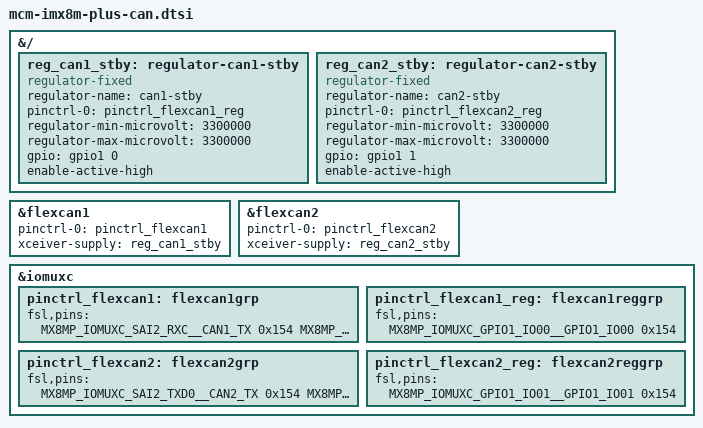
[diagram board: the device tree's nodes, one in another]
&{/} {
	reg_can1_stby: regulator-can1-stby {
		compatible = "regulator-fixed";
		regulator-name = "can1-stby";
		pinctrl-names = "default";
		pinctrl-0 = <&pinctrl_flexcan1_reg>;
		regulator-min-microvolt = <3300000>;
		regulator-max-microvolt = <3300000>;
		gpio = <&gpio1 0 GPIO_ACTIVE_HIGH>;
		enable-active-high;
	};

	reg_can2_stby: regulator-can2-stby {
		compatible = "regulator-fixed";
		regulator-name = "can2-stby";
		pinctrl-names = "default";
		pinctrl-0 = <&pinctrl_flexcan2_reg>;
		regulator-min-microvolt = <3300000>;
		regulator-max-microvolt = <3300000>;
		gpio = <&gpio1 1 GPIO_ACTIVE_HIGH>;
		enable-active-high;
	};
};

&flexcan1 {
	pinctrl-names = "default";
	pinctrl-0 = <&pinctrl_flexcan1>;
	xceiver-supply = <&reg_can1_stby>;
	status = "okay";
};

&flexcan2 {
	pinctrl-names = "default";
	pinctrl-0 = <&pinctrl_flexcan2>;
	xceiver-supply = <&reg_can2_stby>;
	status = "okay";
};

&iomuxc {
	pinctrl_flexcan1: flexcan1grp {
		fsl,pins = <
			MX8MP_IOMUXC_SAI2_RXC__CAN1_TX			0x154
			MX8MP_IOMUXC_SAI2_TXC__CAN1_RX			0x154
		>;
	};

	pinctrl_flexcan2: flexcan2grp {
		fsl,pins = <
			MX8MP_IOMUXC_SAI2_TXD0__CAN2_TX			0x154
			MX8MP_IOMUXC_SAI2_MCLK__CAN2_RX			0x154
		>;
	};

	pinctrl_flexcan1_reg: flexcan1reggrp {
		fsl,pins = <
			MX8MP_IOMUXC_GPIO1_IO00__GPIO1_IO00	0x154	/* CAN1_STBY */
		>;
	};

	pinctrl_flexcan2_reg: flexcan2reggrp {
		fsl,pins = <
			MX8MP_IOMUXC_GPIO1_IO01__GPIO1_IO01	0x154	/* CAN1_STBY */
		>;
	};
};
